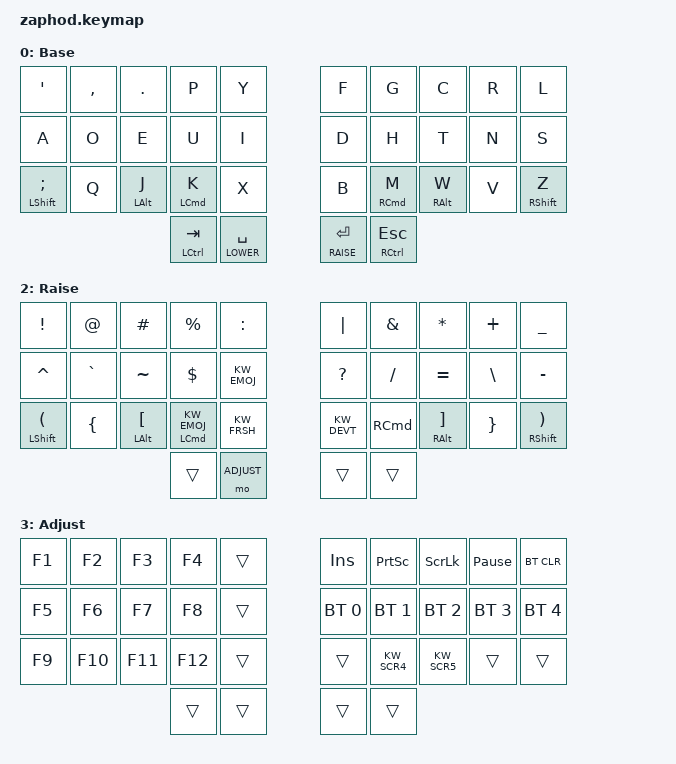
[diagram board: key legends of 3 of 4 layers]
/*
 * Copyright (c) 2021 Pete Johanson
 *
 * SPDX-License-Identifier: MIT
 */

#include <behaviors.dtsi>
#include <dt-bindings/zmk/keys.h>
#include <dt-bindings/zmk/bt.h>
#include <dt-bindings/zmk/outputs.h>

#define DEFAULT 0
#define LOWER   1
#define RAISE   2
#define ADJUST  3

#define KW_FRSH    LG(LS(R))           // browser refresh
#define KW_DEVT    LG(LA(I))           // browser dev tools
#define KW_EMOJ    LG(LC(SPACE))       // macos emoji picker
#define KW_MOOM    LG(LC(M))           // moom window management
#define KW_WINF    LG(GRAVE)           // cmd+` (macos, next window of current app)
#define KW_WINB    LG(TILDE)           // cmd+~ (macos, prev window of current app)

#define KW_UNDO    LG(Z)               // cmd+z (undo)
#define KW_CUT     LG(X)               // cmd+x (cut)
#define KW_COPY    LG(C)               // cmd+c (copy)
#define KW_PASTE   LG(V)               // cmd+v (paste)

#define WORD_L     LA(LEFT)            // alt+left (word left, macos/emacs)
#define WORD_R     LA(RIGHT)           // alt+right (word right, macos/emacs)

#define KW_SCR4    LG(LS(N4))          // screenshot (region, macos)
#define KW_SCR5    LG(LS(N5))          // screenshot (window/etc..., macos)

/ {

    behaviors {
        ht_bl: hold_tap_balanced {
            compatible = "zmk,behavior-hold-tap";
            label = "HOLD_TAP_BALANCED";
            #binding-cells = <2>;
            tapping-term-ms = <200>;
            flavor = "balanced";
            bindings = <&kp>, <&kp>;
        };
    };

    macros {
        ZMK_MACRO(esc_bslash,
            wait-ms = <40>;
            tap-ms = <40>;
            bindings = <&kp ESC>, <&kp BACKSLASH>;
        )

        ZMK_MACRO(bs_four,
            wait-ms = <40>;
            tap-ms = <40>;
            bindings = <&kp BACKSPACE>, <&kp BACKSPACE>, <&kp BACKSPACE>, <&kp BACKSPACE>;
        )

        ZMK_MACRO(del_four,
            wait-ms = <40>;
            tap-ms = <40>;
            bindings = <&kp DEL>, <&kp DEL>, <&kp DEL>, <&kp DEL>;
        )

        ZMK_MACRO(spc_four,
            wait-ms = <40>;
            tap-ms = <40>;
            bindings = <&kp SPACE>, <&kp SPACE>, <&kp SPACE>, <&kp SPACE>;
        )
    };

    keymap {
        compatible = "zmk,keymap";

        default_layer {
            label = "Base";
            bindings = <
            // ╭────────────┬────────────┬────────────┬────────────┬────────────╮   ╭────────────┬────────────┬────────────┬────────────┬────────────╮
                 &kp APOS     &kp COMMA    &kp DOT      &kp P        &kp Y            &kp F        &kp G        &kp C        &kp R        &kp L
                 &kp A        &kp O        &kp E        &kp U        &kp I            &kp D        &kp H        &kp T        &kp N        &kp S
          &ht_bl LSHIFT SEMI  &kp Q    &ht_bl LALT J  &ht_bl LCMD K  &kp X            &kp B      &ht_bl RCMD M  &ht_bl RALT W  &kp V      &ht_bl RSHIFT Z
            // ╰────────────┴────────────┴────────────╮                                                       ╭────────────┴────────────┴────────────╯
                                                  &ht_bl LCTRL TAB   &lt LOWER SPACE  &lt RAISE RET  &ht_bl RCTRL ESC
            //                                        ╰────────────┴────────────╯   ╰────────────┴────────────╯
            >;
        };

        lower_layer {
            label = "Lower";
            bindings = <
            // ╭────────────┬────────────┬────────────┬────────────┬────────────╮   ╭────────────┬────────────┬────────────┬────────────┬────────────╮
                 &kp PG_UP    &kp WORD_L   &kp UP       &kp WORD_R   &kp HOME         &kp DEL      &kp N7       &kp N8       &kp N9       &kp BACKSPACE
                 &kp PG_DN    &kp LEFT     &kp DOWN     &kp RIGHT    &kp END          &trans       &kp N4       &kp N5       &kp N6       &trans
      &trans  &kp KW_WINB  &ht_bl LALT KW_MOOM  &ht_bl LCMD KW_WINF  &trans           &del_four    &ht_bl RCMD N1  &ht_bl RALT N2  &kp N3   &ht_bl RSHIFT &bs_four
            // ╰────────────┴────────────┴────────────╮                                                       ╭────────────┴────────────┴────────────╯
                                                        &spc_four    &trans           &ht_bl RCTRL N0   &esc_bslash
            //                                        ╰────────────┴────────────╯   ╰────────────┴────────────╯
            >;
        };

        raise_layer {
            label = "Raise";
            bindings = <
            // ╭────────────┬────────────┬────────────┬────────────┬────────────╮   ╭────────────┬────────────┬────────────┬────────────┬────────────╮
                 &kp EXCL     &kp AT       &kp HASH     &kp PRCNT    &kp COLON        &kp PIPE     &kp AMPS     &kp STAR     &kp PLUS     &kp UNDER
                 &kp CARET    &kp GRAVE    &kp TILDE    &kp DOLLAR   &kp KW_EMOJ      &kp QMARK    &kp SLASH    &kp EQUAL    &kp BSLH     &kp MINUS
          &ht_bl LSHIFT LPAR  &kp LBRC  &ht_bl LALT LBKT  &ht_bl LCMD KW_EMOJ  &kp KW_FRSH      &kp KW_DEVT  &kp RCMD  &ht_bl RALT RBKT  &kp RBRC  &ht_bl RSHIFT RPAR
            // ╰────────────┴────────────┴────────────╮                                                       ╭────────────┴────────────┴────────────╯
                                                        &trans       &mo ADJUST       &trans       &trans
            //                                        ╰────────────┴────────────╯   ╰────────────┴────────────╯
            >;
        };

        adjust_layer {
            label = "Adjust";
            bindings = <
            // ╭────────────┬────────────┬────────────┬────────────┬────────────╮   ╭────────────┬────────────┬────────────┬────────────┬────────────╮
                 &kp F1       &kp F2       &kp F3       &kp F4       &trans           &kp INS       &kp PSCRN     &kp SLCK      &kp PAUSE_BREAK  &bt BT_CLR
                 &kp F5       &kp F6       &kp F7       &kp F8       &trans           &bt BT_SEL 0  &bt BT_SEL 1  &bt BT_SEL 2  &bt BT_SEL 3  &bt BT_SEL 4
                 &kp F9       &kp F10      &kp F11      &kp F12      &trans           &trans        &kp KW_SCR4   &kp KW_SCR5   &trans     &trans
            // ╰────────────┴────────────┴────────────╮                                                       ╭────────────┴────────────┴────────────╯
                                                        &trans       &trans           &trans       &trans
            //                                        ╰────────────┴────────────╯   ╰────────────┴────────────╯
            >;
        };
    };
};
